# GD32F5HC register map
File version: 1.0
CPU: CM33 r0p4, little endian, MPU, FPU, 4 interrupt priority bits
Registers are 32-bit, read-write, reset 0x0 unless marked. A register's access mark holds for its fields unless they carry their own. Offsets are from the block's base; [hi:lo] are bit positions; {n}, {i} and the like mark numbered series.

## FS_PWRCLK — USB on the go full speed
Base 0x49000E00
Same registers: SEC_FS_PWRCLK 0x59000E00
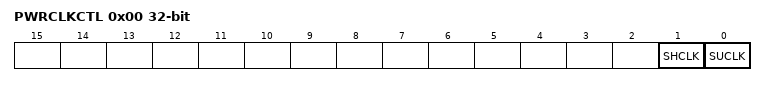
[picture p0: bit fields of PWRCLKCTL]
0x00 PWRCLKCTL — power and clock gating control register (PWRCLKCTL)
  [1] SHCLK — Stop HCLK
  [0] SUCLK — Stop the USB clock

## FWDGT — free watchdog timer
Base 0x40003000
Same registers: SEC_FWDGT 0x50003000
0x00 CTL wo — Control register
  [15:0] CMD — Key value
0x04 PSC — Prescaler register
  [2:0] PSC — Prescaler divider
0x08 RLD reset 0xFFF — Reload register
  [11:0] RLD — Free watchdog timer counter reload value
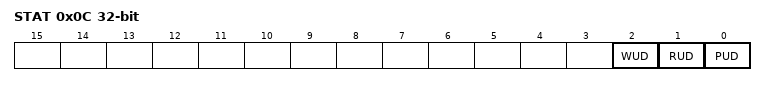
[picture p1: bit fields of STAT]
0x0C STAT ro — Status register
  [2] WUD — Watchdog counter window value update
  [1] RUD — Free watchdog timer counter reload value update
  [0] PUD — Free watchdog timer prescaler value update
0x10 WND reset 0xFFF — Window register
  [11:0] WND — Watchdog counter window value

## HAU — HAU acceleration unit
Base 0x4C060400
Same registers: SEC_HAU 0x5C060400
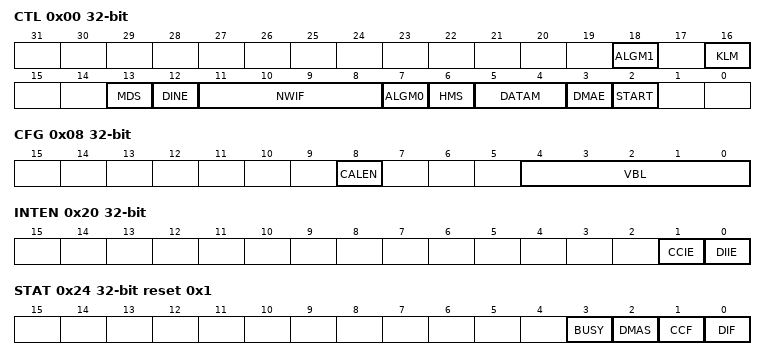
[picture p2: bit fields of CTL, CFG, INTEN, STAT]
0x00 CTL access per field — HAU control register
  [18] ALGM1 rw — Algorithm selection bit 1
  [16] KLM rw — Key length mode
  [13] MDS rw — Multiple DMA selection
  [12] DINE ro — DI register is not empty
  [11:8] NWIF ro — Number of words in IN FIFO
  [7] ALGM0 rw — Algorithm selection bit 0
  [6] HMS rw — HAU mode selection
  [5:4] DATAM rw — Data type mode
  [3] DMAE rw — DMA enable
  [2] START wo — Start message digest calculation
0x04 DI — HAU data input register
  [31:0] DI — Message data input
0x08 CFG access per field — HAU configuration register
  [8] CALEN wo — Digest calculation enable
  [4:0] VBL rw — Valid bits length in the last word
{0xC+4i} DO{i} ro (i=0..4) — HAU data output register
  [31:0] DO{i} — message digest result of hash algorithm
0x20 INTEN — HAU interrupt enable register
  [1] CCIE — calculation completion interrupt enable
  [0] DIIE — Data input interrupt enable
0x24 STAT ro reset 0x1 — HAU status and interrupt flag register
  [3] BUSY — Busy flag bit
  [2] DMAS — DMA status flag
  [1] CCF — Digest calculation completion flag
  [0] DIF — Data input flag
0xF8 CTXS0 reset 0x2 — Context switch register x
  [31:0] CTX0 — The complete internal status
{0xF8+4i} CTXS{i} (i=1..53) — Context switch register x
  [31:0] CTX{i} — The complete internal status
{0x310+4i} DO{i} ro (i=5..7) — HAU data output register
  [31:0] DO{i} — message digest result of hash algorithm

## ICACHE
Base 0x40080000
Same registers: SEC_ICACHE 0x50080000
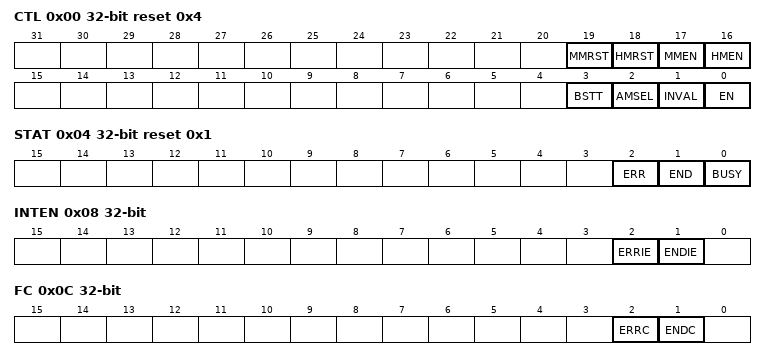
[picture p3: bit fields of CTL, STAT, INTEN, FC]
0x00 CTL reset 0x4 — Control register
  [19] MMRST — Miss monitor reset
  [18] HMRST — Hit monitor reset
  [17] MMEN — Miss monitor enable
  [16] HMEN — Hit monitor enable
  [3] BSTT — Burst type for fast bus
  [2] AMSEL — Cache set-associativity mode selection
  [1] INVAL — Cache invalidation, Set by software and cleared by hardware
  [0] EN — cache enabled
0x04 STAT ro reset 0x1 — Status register
  [2] ERR — Cache error flag
  [1] END — operation end flag
  [0] BUSY — Busy flag
0x08 INTEN — Interrupt enable register
  [2] ERRIE — cache error interrupt enable
  [1] ENDIE — cache operation end interrupt enable
0x0C FC wo — Flag clear register
  [2] ERRC — Software clear cache error flag
  [1] ENDC — Software clear operation end flag
0x10 HMC ro — Hit monitor counter register
  [31:0] HMC — Cache hit monitor counter
0x14 MMC ro — Miss monitor counter register
  [15:0] MMC — Cache miss monitor counter
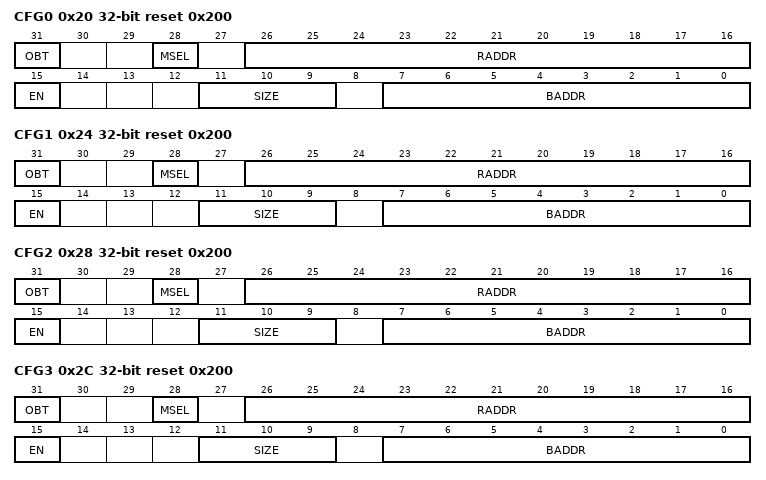
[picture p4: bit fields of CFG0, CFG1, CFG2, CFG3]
0x20 CFG0 reset 0x200 — Configuration register 0
  [31] OBT — Output burst type for region 0
  [28] MSEL — Region 0 AHB cache master selection
  [26:16] RADDR — Region 0 remapped address, this field replaces the alias address defined by BADDR field.
  [15] EN — Region 0 enable
  [11:9] SIZE — Region 0 size
  [7:0] BADDR — Region 0 base address
0x24 CFG1 reset 0x200 — Configuration register 1
  [31] OBT — Output burst type for region 1
  [28] MSEL — Region 1 AHB cache master selection
  [26:16] RADDR — Region 1 remapped address, this field replaces the alias address defined by BADDR field.
  [15] EN — Region 1 enable
  [11:9] SIZE — Region 1 size
  [7:0] BADDR — Region 1 base address
0x28 CFG2 reset 0x200 — Configuration register
  [31] OBT — Output burst type for region 2
  [28] MSEL — Region 2 AHB cache master selection
  [26:16] RADDR — Region 2 remapped address, this field replaces the alias address defined by BADDR field.
  [15] EN — Region 2 enable
  [11:9] SIZE — Region 2 size
  [7:0] BADDR — Region 2 base address
0x2C CFG3 reset 0x200 — Configuration register
  [31] OBT — Output burst type for region 3
  [28] MSEL — Region 3 AHB cache master selection
  [26:16] RADDR — Region 3 remapped address, this field replaces the alias address defined by BADDR field.
  [15] EN — Region 3 enable
  [11:9] SIZE — Region 3 size
  [7:0] BADDR — Region 3 base address
